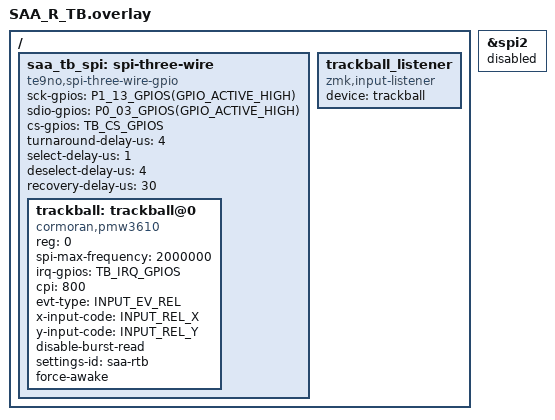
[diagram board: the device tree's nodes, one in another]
#include "SAA_pins.dtsi"

/ {
    saa_tb_spi: spi-three-wire {
        compatible = "te9no,spi-three-wire-gpio";
        status = "okay";
        #address-cells = <1>;
        #size-cells = <0>;

        sck-gpios = P1_13_GPIOS(GPIO_ACTIVE_HIGH);
        sdio-gpios = P0_03_GPIOS(GPIO_ACTIVE_HIGH);
        cs-gpios = TB_CS_GPIOS;

        turnaround-delay-us = <4>;
        select-delay-us = <1>;
        deselect-delay-us = <4>;
        recovery-delay-us = <30>;

        trackball: trackball@0 {
            status = "okay";
            compatible = "cormoran,pmw3610";
            reg = <0>;
            spi-max-frequency = <2000000>;
            irq-gpios = TB_IRQ_GPIOS;
            cpi = <800>;
            evt-type = <INPUT_EV_REL>;
            x-input-code = <INPUT_REL_X>;
            y-input-code = <INPUT_REL_Y>;
            disable-burst-read;
            settings-id = "saa-rtb";
            force-awake;
        };
    };

    trackball_listener: trackball_listener {
        compatible = "zmk,input-listener";
        status = "okay";
        device = <&trackball>;
    };
};

&spi2 {
    status = "disabled";
};
